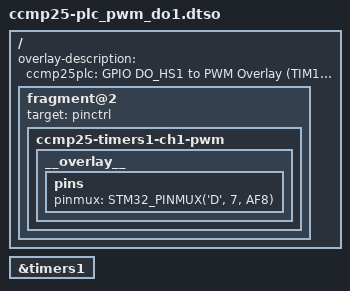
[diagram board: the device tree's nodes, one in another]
/dts-v1/;
/plugin/;

#include <dt-bindings/pinctrl/stm32-pinfunc.h>

/ {

    fragment@0 {
        target-path = "/";
        __overlay__ {
            overlay-description = "ccmp25plc: GPIO DO_HS1 to PWM Overlay (TIM1_CH1 on PD7)";
        };
    };

    fragment@1 {
        target = <&timers1>;
        __overlay__ {
            status = "okay"; 
        };
    };

    fragment@2 {
        target = <&pinctrl>;
        ccmp25-timers1-ch1-pwm {
            __overlay__ {
                pins {
                    /* convert to pwm ：GPIO -> AF8 */
                    pinmux = <STM32_PINMUX('D', 7, AF8)>;                  
                };
            };
        };
    };
};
